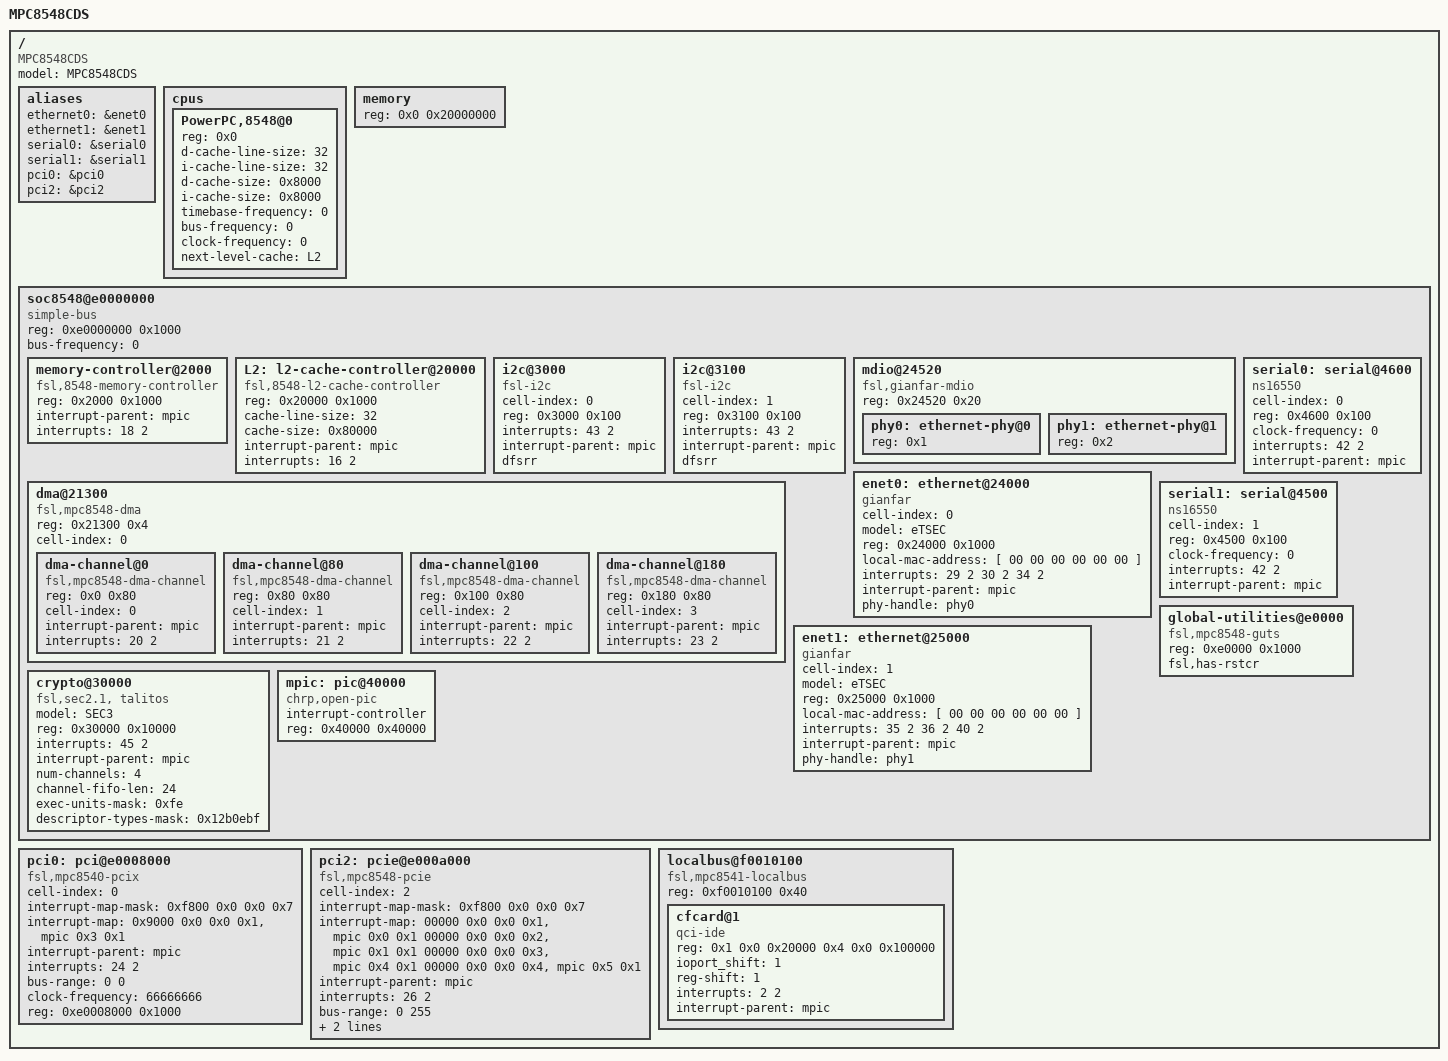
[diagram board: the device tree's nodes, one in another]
/*
 * MPC8548 CDS Device Tree Source
 *
 * Copyright 2006, 2008 Freescale Semiconductor Inc.
 *
 * This program is free software; you can redistribute  it and/or modify it
 * under  the terms of  the GNU General  Public License as published by the
 * Free Software Foundation;  either version 2 of the  License, or (at your
 * option) any later version.
 */

/dts-v1/;

/ {
	model = "MPC8548CDS";
	compatible = "MPC8548CDS", "MPC85xxCDS";
	#address-cells = <1>;
	#size-cells = <1>;

	aliases {
		ethernet0 = &enet0;
		ethernet1 = &enet1;
/*
		ethernet2 = &enet2;
		ethernet3 = &enet3;
*/
		serial0 = &serial0;
		serial1 = &serial1;
		pci0 = &pci0;
/*		pci1 = &pci1;*/
		pci2 = &pci2;
	};

	cpus {
		#address-cells = <1>;
		#size-cells = <0>;

		PowerPC,8548@0 {
			device_type = "cpu";
			reg = <0x0>;
			d-cache-line-size = <32>;	// 32 bytes
			i-cache-line-size = <32>;	// 32 bytes
			d-cache-size = <0x8000>;		// L1, 32K
			i-cache-size = <0x8000>;		// L1, 32K
			timebase-frequency = <0>;	//  33 MHz, from uboot
			bus-frequency = <0>;	// 166 MHz
			clock-frequency = <0>;	// 825 MHz, from uboot
			next-level-cache = <&L2>;
		};
	};

	memory {
		device_type = "memory";
		reg = <0x0 0x20000000>;	// 512M at 0x0
	};

	soc8548@e0000000 {
		#address-cells = <1>;
		#size-cells = <1>;
		device_type = "soc";
		compatible = "simple-bus";
		ranges = <0x0 0xe0000000 0x100000>;
		reg = <0xe0000000 0x1000>;	// CCSRBAR
		bus-frequency = <0>;

		memory-controller@2000 {
			compatible = "fsl,8548-memory-controller";
			reg = <0x2000 0x1000>;
			interrupt-parent = <&mpic>;
			interrupts = <18 2>;
		};

		L2: l2-cache-controller@20000 {
			compatible = "fsl,8548-l2-cache-controller";
			reg = <0x20000 0x1000>;
			cache-line-size = <32>;	// 32 bytes
			cache-size = <0x80000>;	// L2, 512K
			interrupt-parent = <&mpic>;
			interrupts = <16 2>;
		};

		i2c@3000 {
			#address-cells = <1>;
			#size-cells = <0>;
			cell-index = <0>;
			compatible = "fsl-i2c";
			reg = <0x3000 0x100>;
			interrupts = <43 2>;
			interrupt-parent = <&mpic>;
			dfsrr;
		};

		i2c@3100 {
			#address-cells = <1>;
			#size-cells = <0>;
			cell-index = <1>;
			compatible = "fsl-i2c";
			reg = <0x3100 0x100>;
			interrupts = <43 2>;
			interrupt-parent = <&mpic>;
			dfsrr;
		};

		dma@21300 {
			#address-cells = <1>;
			#size-cells = <1>;
			compatible = "fsl,mpc8548-dma", "fsl,eloplus-dma";
			reg = <0x21300 0x4>;
			ranges = <0x0 0x21100 0x200>;
			cell-index = <0>;
			dma-channel@0 {
				compatible = "fsl,mpc8548-dma-channel",
						"fsl,eloplus-dma-channel";
				reg = <0x0 0x80>;
				cell-index = <0>;
				interrupt-parent = <&mpic>;
				interrupts = <20 2>;
			};
			dma-channel@80 {
				compatible = "fsl,mpc8548-dma-channel",
						"fsl,eloplus-dma-channel";
				reg = <0x80 0x80>;
				cell-index = <1>;
				interrupt-parent = <&mpic>;
				interrupts = <21 2>;
			};
			dma-channel@100 {
				compatible = "fsl,mpc8548-dma-channel",
						"fsl,eloplus-dma-channel";
				reg = <0x100 0x80>;
				cell-index = <2>;
				interrupt-parent = <&mpic>;
				interrupts = <22 2>;
			};
			dma-channel@180 {
				compatible = "fsl,mpc8548-dma-channel",
						"fsl,eloplus-dma-channel";
				reg = <0x180 0x80>;
				cell-index = <3>;
				interrupt-parent = <&mpic>;
				interrupts = <23 2>;
			};
		};

		mdio@24520 {
			#address-cells = <1>;
			#size-cells = <0>;
			compatible = "fsl,gianfar-mdio";
			reg = <0x24520 0x20>;

			phy0: ethernet-phy@0 {
//				interrupt-parent = <&mpic>;
//				interrupts = <5 1>;
				reg = <0x1>;
				device_type = "ethernet-phy";
			};
			phy1: ethernet-phy@1 {
//				interrupt-parent = <&mpic>;
//				interrupts = <5 1>;
				reg = <0x2>;
				device_type = "ethernet-phy";
			};
/*			phy2: ethernet-phy@2 {
				interrupt-parent = <&mpic>;
				interrupts = <5 1>;
				reg = <0x2>;
				device_type = "ethernet-phy";
			};
			phy3: ethernet-phy@3 {
				interrupt-parent = <&mpic>;
				interrupts = <5 1>;
				reg = <0x3>;
				device_type = "ethernet-phy";
			};*/
		};

		enet0: ethernet@24000 {
			cell-index = <0>;
			device_type = "network";
			model = "eTSEC";
			compatible = "gianfar";
			reg = <0x24000 0x1000>;
			local-mac-address = [ 00 00 00 00 00 00 ];
			interrupts = <29 2 30 2 34 2>;
			interrupt-parent = <&mpic>;
			phy-handle = <&phy0>;
		};

		enet1: ethernet@25000 {
			cell-index = <1>;
			device_type = "network";
			model = "eTSEC";
			compatible = "gianfar";
			reg = <0x25000 0x1000>;
			local-mac-address = [ 00 00 00 00 00 00 ];
			interrupts = <35 2 36 2 40 2>;
			interrupt-parent = <&mpic>;
			phy-handle = <&phy1>;
		};

/* eTSEC 3/4 are currently broken
		enet2: ethernet@26000 {
			cell-index = <2>;
			device_type = "network";
			model = "eTSEC";
			compatible = "gianfar";
			reg = <0x26000 0x1000>;
			local-mac-address = [ 00 00 00 00 00 00 ];
			interrupts = <31 2 32 2 33 2>;
			interrupt-parent = <&mpic>;
			phy-handle = <&phy2>;
		};

		enet3: ethernet@27000 {
			cell-index = <3>;
			device_type = "network";
			model = "eTSEC";
			compatible = "gianfar";
			reg = <0x27000 0x1000>;
			local-mac-address = [ 00 00 00 00 00 00 ];
			interrupts = <37 2 38 2 39 2>;
			interrupt-parent = <&mpic>;
			phy-handle = <&phy3>;
		};
 */

		serial0: serial@4600 {
			cell-index = <0>;
			device_type = "serial";
			compatible = "ns16550";
			reg = <0x4600 0x100>;	// reg base, size
			clock-frequency = <0>;	// should we fill in in uboot?
			interrupts = <42 2>;
			interrupt-parent = <&mpic>;
		};

		serial1: serial@4500 {
			cell-index = <1>;
			device_type = "serial";
			compatible = "ns16550";
			reg = <0x4500 0x100>;	// reg base, size
			clock-frequency = <0>;	// should we fill in in uboot?
			interrupts = <42 2>;
			interrupt-parent = <&mpic>;
		};

		global-utilities@e0000 {	//global utilities reg
			compatible = "fsl,mpc8548-guts";
			reg = <0xe0000 0x1000>;
			fsl,has-rstcr;
		};
		crypto@30000 {
			device_type = "crypto";
                        compatible = "fsl,sec2.1, talitos", "fsl,sec2.0, talitos";
			model = "SEC3";
			reg = <0x30000 0x10000>;
			interrupts = <45 2>;
			interrupt-parent = <&mpic>;
                        num-channels = <4>;
                        channel-fifo-len = <24>;
                        exec-units-mask = <0xfe>;
                        descriptor-types-mask = <0x12b0ebf>;
		};

		mpic: pic@40000 {
			interrupt-controller;
			#address-cells = <0>;
			#interrupt-cells = <2>;
			reg = <0x40000 0x40000>;
			compatible = "chrp,open-pic";
			device_type = "open-pic";
		};
	};

	pci0: pci@e0008000 {
		cell-index = <0>;
		interrupt-map-mask = <0xf800 0x0 0x0 0x7>;
		interrupt-map = <

			/* IDSEL 0x12 (Slot 1) */
			0x9000 0x0 0x0 0x1 &mpic 0x3 0x1
		>;

		interrupt-parent = <&mpic>;
		interrupts = <24 2>;
		bus-range = <0 0>;
		ranges = <0x2000000 0x0 0x80000000 0x80000000 0x0 0x10000000
			  0x1000000 0x0 0x0 0xe2000000 0x0 0x800000>;
		clock-frequency = <66666666>;
		#interrupt-cells = <1>;
		#size-cells = <2>;
		#address-cells = <3>;
		reg = <0xe0008000 0x1000>;
		compatible = "fsl,mpc8540-pcix", "fsl,mpc8540-pci";
		device_type = "pci";

	};


	pci2: pcie@e000a000 {
		cell-index = <2>;
		interrupt-map-mask = <0xf800 0x0 0x0 0x7>;
		interrupt-map = <

			/* IDSEL 0x0 (PEX) */
			00000 0x0 0x0 0x1 &mpic 0x0 0x1
			00000 0x0 0x0 0x2 &mpic 0x1 0x1
			00000 0x0 0x0 0x3 &mpic 0x4 0x1
			00000 0x0 0x0 0x4 &mpic 0x5 0x1>;

		interrupt-parent = <&mpic>;
		interrupts = <26 2>;
		bus-range = <0 255>;
		ranges = <0x2000000 0x0 0xa0000000 0xa0000000 0x0 0x20000000
			  0x1000000 0x0 0x0 0xe3000000 0x0 0x100000>;
		clock-frequency = <33333333>;
		#interrupt-cells = <1>;
		#size-cells = <2>;
		#address-cells = <3>;
		reg = <0xe000a000 0x1000>;
		compatible = "fsl,mpc8548-pcie";
		device_type = "pci";
	};
	
	
	localbus@f0010100 {
		#address-cells = <2>; 
		#size-cells = <1>;
		compatible = "fsl,mpc8541-localbus",
		"fsl,pq2-localbus",
		"simple-bus"; 
		reg = <0xf0010100 0x40>;
		ranges = <0x0 0x0 0xfe000000 0x2000000 
		0x1 0x0 0xf0000000 0x20000 
		0x2 0x0 0xf0010000 0x10000
		0x3 0x0 0xf2000000 0x100000
		0x4 0x0 0xe0000000 0x2>; 

		 cfcard@1 {
		 	compatible = "qci-ide";
			device_type = "ide";
			reg = <0x1 0x0 0x20000 0x4 0x0 0x100000>;
			ioport_shift = <1>;
			reg-shift = <1>; 
			#interrupt-cells = <1>;
			interrupts = <2 2>;
			interrupt-parent = <&mpic>;
		 }; 
	};
};
